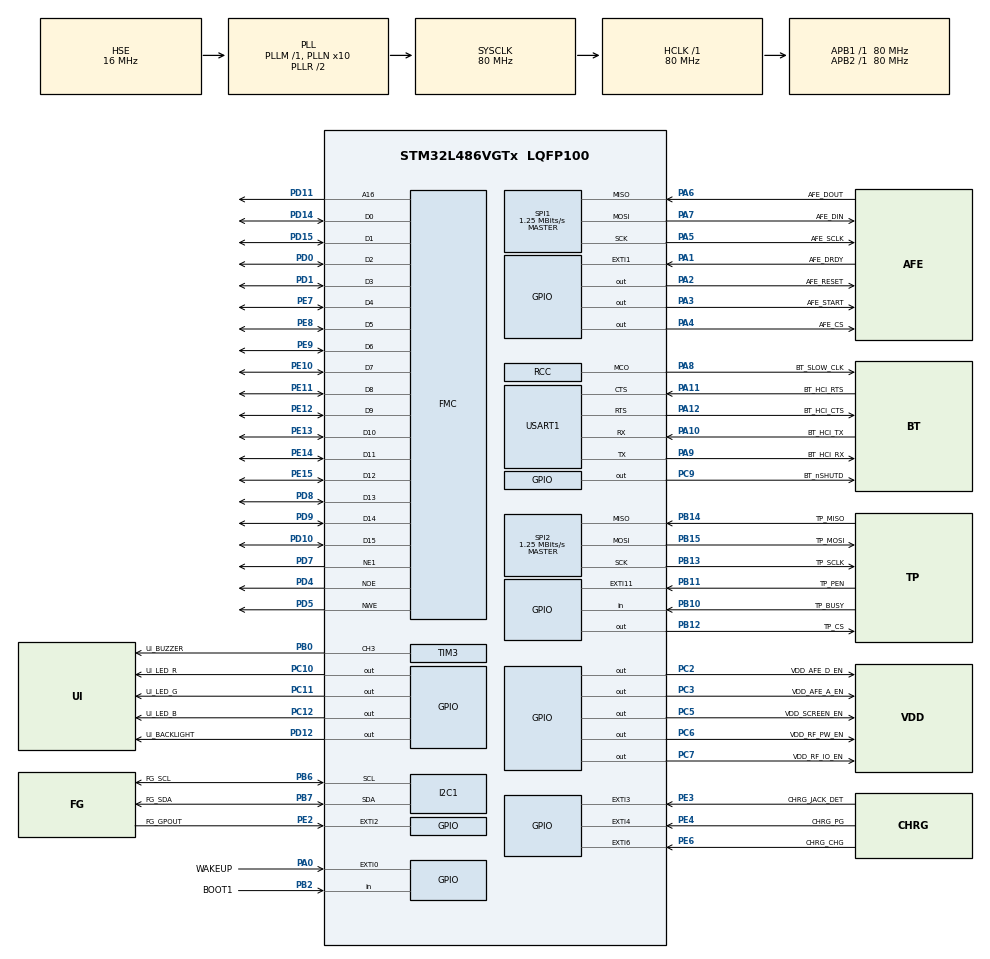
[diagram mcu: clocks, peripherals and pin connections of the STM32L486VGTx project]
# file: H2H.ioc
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Dma.I2C1_RX.1.Direction=DMA_PERIPH_TO_MEMORY
Dma.I2C1_RX.1.Instance=DMA1_Channel7
Dma.I2C1_RX.1.MemDataAlignment=DMA_MDATAALIGN_BYTE
Dma.I2C1_RX.1.MemInc=DMA_MINC_ENABLE
Dma.I2C1_RX.1.Mode=DMA_NORMAL
Dma.I2C1_RX.1.PeriphDataAlignment=DMA_PDATAALIGN_BYTE
Dma.I2C1_RX.1.PeriphInc=DMA_PINC_DISABLE
Dma.I2C1_RX.1.Priority=DMA_PRIORITY_LOW
Dma.I2C1_TX.0.Direction=DMA_MEMORY_TO_PERIPH
Dma.I2C1_TX.0.Instance=DMA1_Channel6
Dma.I2C1_TX.0.MemDataAlignment=DMA_MDATAALIGN_BYTE
Dma.I2C1_TX.0.MemInc=DMA_MINC_ENABLE
Dma.I2C1_TX.0.Mode=DMA_NORMAL
Dma.I2C1_TX.0.PeriphDataAlignment=DMA_PDATAALIGN_BYTE
Dma.I2C1_TX.0.PeriphInc=DMA_PINC_DISABLE
Dma.I2C1_TX.0.Priority=DMA_PRIORITY_LOW
Dma.MEMTOMEM.8.Direction=DMA_MEMORY_TO_MEMORY
Dma.MEMTOMEM.8.Instance=DMA2_Channel1
Dma.MEMTOMEM.8.MemDataAlignment=DMA_MDATAALIGN_BYTE
Dma.MEMTOMEM.8.MemInc=DMA_MINC_DISABLE
Dma.MEMTOMEM.8.Mode=DMA_NORMAL
Dma.MEMTOMEM.8.PeriphDataAlignment=DMA_PDATAALIGN_BYTE
Dma.MEMTOMEM.8.PeriphInc=DMA_PINC_DISABLE
Dma.MEMTOMEM.8.Priority=DMA_PRIORITY_LOW
Dma.Request0=I2C1_TX
Dma.Request1=I2C1_RX
Dma.Request2=SPI1_TX
Dma.Request3=SPI1_RX
Dma.Request4=SPI2_TX
Dma.Request5=SPI2_RX
Dma.Request6=USART1_TX
Dma.Request7=USART1_RX
Dma.Request8=MEMTOMEM
Dma.SPI1_RX.3.Direction=DMA_PERIPH_TO_MEMORY
Dma.SPI1_RX.3.Instance=DMA1_Channel2
Dma.SPI1_RX.3.MemDataAlignment=DMA_MDATAALIGN_BYTE
Dma.SPI1_RX.3.MemInc=DMA_MINC_ENABLE
Dma.SPI1_RX.3.Mode=DMA_NORMAL
Dma.SPI1_RX.3.PeriphDataAlignment=DMA_PDATAALIGN_BYTE
Dma.SPI1_RX.3.PeriphInc=DMA_PINC_DISABLE
Dma.SPI1_RX.3.Priority=DMA_PRIORITY_VERY_HIGH
Dma.SPI1_TX.2.Direction=DMA_MEMORY_TO_PERIPH
Dma.SPI1_TX.2.Instance=DMA1_Channel3
Dma.SPI1_TX.2.MemDataAlignment=DMA_MDATAALIGN_BYTE
Dma.SPI1_TX.2.MemInc=DMA_MINC_ENABLE
Dma.SPI1_TX.2.Mode=DMA_NORMAL
Dma.SPI1_TX.2.PeriphDataAlignment=DMA_PDATAALIGN_BYTE
Dma.SPI1_TX.2.PeriphInc=DMA_PINC_DISABLE
Dma.SPI1_TX.2.Priority=DMA_PRIORITY_VERY_HIGH
Dma.SPI2_RX.5.Direction=DMA_PERIPH_TO_MEMORY
Dma.SPI2_RX.5.Instance=DMA1_Channel4
Dma.SPI2_RX.5.MemDataAlignment=DMA_MDATAALIGN_BYTE
Dma.SPI2_RX.5.MemInc=DMA_MINC_ENABLE
Dma.SPI2_RX.5.Mode=DMA_NORMAL
Dma.SPI2_RX.5.PeriphDataAlignment=DMA_PDATAALIGN_BYTE
Dma.SPI2_RX.5.PeriphInc=DMA_PINC_DISABLE
Dma.SPI2_RX.5.Priority=DMA_PRIORITY_MEDIUM
Dma.SPI2_TX.4.Direction=DMA_MEMORY_TO_PERIPH
Dma.SPI2_TX.4.Instance=DMA1_Channel5
Dma.SPI2_TX.4.MemDataAlignment=DMA_MDATAALIGN_BYTE
Dma.SPI2_TX.4.MemInc=DMA_MINC_ENABLE
Dma.SPI2_TX.4.Mode=DMA_NORMAL
Dma.SPI2_TX.4.PeriphDataAlignment=DMA_PDATAALIGN_BYTE
Dma.SPI2_TX.4.PeriphInc=DMA_PINC_DISABLE
Dma.SPI2_TX.4.Priority=DMA_PRIORITY_MEDIUM
Dma.USART1_RX.7.Direction=DMA_PERIPH_TO_MEMORY
Dma.USART1_RX.7.Instance=DMA2_Channel7
Dma.USART1_RX.7.MemDataAlignment=DMA_MDATAALIGN_BYTE
Dma.USART1_RX.7.MemInc=DMA_MINC_ENABLE
Dma.USART1_RX.7.Mode=DMA_NORMAL
Dma.USART1_RX.7.PeriphDataAlignment=DMA_PDATAALIGN_BYTE
Dma.USART1_RX.7.PeriphInc=DMA_PINC_DISABLE
Dma.USART1_RX.7.Priority=DMA_PRIORITY_HIGH
Dma.USART1_TX.6.Direction=DMA_MEMORY_TO_PERIPH
Dma.USART1_TX.6.Instance=DMA2_Channel6
Dma.USART1_TX.6.MemDataAlignment=DMA_MDATAALIGN_BYTE
Dma.USART1_TX.6.MemInc=DMA_MINC_ENABLE
Dma.USART1_TX.6.Mode=DMA_NORMAL
Dma.USART1_TX.6.PeriphDataAlignment=DMA_PDATAALIGN_BYTE
Dma.USART1_TX.6.PeriphInc=DMA_PINC_DISABLE
Dma.USART1_TX.6.Priority=DMA_PRIORITY_HIGH
FMC.AddressSetupTime1=5
FMC.BusTurnAroundDuration1=5
FMC.DataSetupTime1=5
FREERTOS.Tasks01=defaultTask,0,128,StartDefaultTask,Default
FREERTOS.configCHECK_FOR_STACK_OVERFLOW=2
FREERTOS.configMAX_TASK_NAME_LEN=24
FREERTOS.configMINIMAL_STACK_SIZE=64
FREERTOS.configTOTAL_HEAP_SIZE=64000
FREERTOS.configUSE_COUNTING_SEMAPHORES=1
FREERTOS.configUSE_RECURSIVE_MUTEXES=1
FREERTOS.configUSE_TICKLESS_IDLE=1
I2C1.Analog_Filter=I2C_ANALOGFILTER_DISABLE
I2C1.Speed=50
I2C1.Timing=0x30408EFF
Mcu.Family=STM32L4
Mcu.Name=STM32L486VGTx
Mcu.Package=LQFP100
NVIC.DMA1_Channel2_IRQn=true\:6\:0\:true\:false\:true\:true
NVIC.DMA1_Channel3_IRQn=true\:6\:0\:true\:false\:true\:true
NVIC.DMA1_Channel4_IRQn=true\:8\:0\:true\:false\:true\:true
NVIC.DMA1_Channel5_IRQn=true\:8\:0\:true\:false\:true\:true
NVIC.DMA1_Channel6_IRQn=true\:9\:0\:true\:false\:true\:true
NVIC.DMA1_Channel7_IRQn=true\:9\:0\:true\:false\:true\:true
NVIC.DMA2_Channel6_IRQn=true\:7\:0\:true\:false\:true\:true
NVIC.DMA2_Channel7_IRQn=true\:7\:0\:true\:false\:true\:true
NVIC.EXTI0_IRQn=true\:5\:0\:false\:false\:true\:true
NVIC.EXTI15_10_IRQn=true\:7\:0\:true\:false\:true\:true
NVIC.EXTI1_IRQn=true\:6\:0\:true\:false\:true\:true
NVIC.EXTI2_IRQn=true\:8\:0\:true\:false\:true\:true
NVIC.EXTI3_IRQn=true\:8\:0\:true\:false\:true\:true
NVIC.EXTI4_IRQn=true\:8\:0\:true\:false\:true\:true
NVIC.EXTI9_5_IRQn=true\:5\:0\:true\:false\:true\:true
NVIC.PriorityGroup=NVIC_PRIORITYGROUP_4
NVIC.RTC_Alarm_IRQn=true\:10\:0\:true\:false\:true\:true
NVIC.TIM4_IRQn=true\:10\:0\:true\:false\:true\:true
PA0.GPIO_Label=WAKEUP
PA0.Signal=GPXTI0
PA1.GPIO_Label=AFE_DRDY
PA1.Signal=GPXTI1
PA10.GPIO_Label=BT_HCI_TX
PA10.Mode=Asynchronous
PA10.Signal=USART1_RX
PA11.GPIO_Label=BT_HCI_RTS
PA11.Mode=CTS_RTS
PA11.Signal=USART1_CTS
PA12.GPIO_Label=BT_HCI_CTS
PA12.Mode=CTS_RTS
PA12.Signal=USART1_RTS
PA13.Mode=Serial_Wire
PA13.Signal=SYS_JTMS-SWDIO
PA14.Mode=Serial_Wire
PA14.Signal=SYS_JTCK-SWCLK
PA2.GPIO_Label=AFE_RESET
PA2.PinState=GPIO_PIN_RESET
PA2.Signal=GPIO_Output
PA3.GPIO_Label=AFE_START
PA3.Signal=GPIO_Output
PA4.GPIO_Label=AFE_CS
PA4.PinState=GPIO_PIN_RESET
PA4.Signal=GPIO_Output
PA5.GPIO_Label=AFE_SCLK
PA5.Mode=Full_Duplex_Master
PA5.Signal=SPI1_SCK
PA6.GPIO_Label=AFE_DOUT
PA6.Mode=Full_Duplex_Master
PA6.Signal=SPI1_MISO
PA7.GPIO_Label=AFE_DIN
PA7.Mode=Full_Duplex_Master
PA7.Signal=SPI1_MOSI
PA8.GPIO_Label=BT_SLOW_CLK
PA8.Mode=Clock-out
PA8.Signal=RCC_MCO
PA9.GPIO_Label=BT_HCI_RX
PA9.Mode=Asynchronous
PA9.Signal=USART1_TX
PB0.GPIO_Label=UI_BUZZER
PB0.Signal=S_TIM3_CH3
PB10.GPIO_Label=TP_BUSY
PB10.Signal=GPIO_Input
PB11.GPIO_Label=TP_PEN
PB11.Signal=GPXTI11
PB12.GPIO_Label=TP_CS
PB12.PinState=GPIO_PIN_RESET
PB12.Signal=GPIO_Output
PB13.GPIO_Label=TP_SCLK
PB13.Mode=Full_Duplex_Master
PB13.Signal=SPI2_SCK
PB14.GPIO_Label=TP_MISO
PB14.Mode=Full_Duplex_Master
PB14.Signal=SPI2_MISO
PB15.GPIO_Label=TP_MOSI
PB15.Mode=Full_Duplex_Master
PB15.Signal=SPI2_MOSI
PB2.GPIO_Label=BOOT1
PB2.Signal=GPIO_Input
PB6.GPIO_Label=FG_SCL
PB6.Mode=I2C
PB6.Signal=I2C1_SCL
PB7.GPIO_Label=FG_SDA
PB7.Mode=I2C
PB7.Signal=I2C1_SDA
PC10.GPIO_Label=UI_LED_R
PC10.Signal=GPIO_Output
PC11.GPIO_Label=UI_LED_G
PC11.Signal=GPIO_Output
PC12.GPIO_Label=UI_LED_B
PC12.Signal=GPIO_Output
PC14/OSC32_IN.GPIO_Label=OSC32_IN
PC14/OSC32_IN.Mode=LSE-External-Oscillator
PC14/OSC32_IN.Signal=RCC_OSC32_IN
PC15/OSC32_OUT.GPIO_Label=OSC32_OUT
PC15/OSC32_OUT.Mode=LSE-External-Oscillator
PC15/OSC32_OUT.Signal=RCC_OSC32_OUT
PC2.GPIO_Label=VDD_AFE_D_EN
PC2.Signal=GPIO_Output
PC3.GPIO_Label=VDD_AFE_A_EN
PC3.Signal=GPIO_Output
PC5.GPIO_Label=VDD_SCREEN_EN
PC5.Signal=GPIO_Output
PC6.GPIO_Label=VDD_RF_PW_EN
PC6.Signal=GPIO_Output
PC7.GPIO_Label=VDD_RF_IO_EN
PC7.Signal=GPIO_Output
PC9.GPIO_Label=BT_nSHUTD
PC9.Signal=GPIO_Output
PD0.Mode=16b-d1
PD0.Signal=FMC_D2
PD1.Mode=16b-d1
PD1.Signal=FMC_D3
PD10.Mode=16b-d1
PD10.Signal=FMC_D15
PD11.Mode=A16_1
PD11.Signal=FMC_A16
PD12.GPIO_Label=UI_BACKLIGHT
PD12.Signal=GPIO_Output
PD14.Mode=16b-d1
PD14.Signal=FMC_D0
PD15.Mode=16b-d1
PD15.Signal=FMC_D1
PD4.Mode=Lcd1
PD4.Signal=FMC_NOE
PD5.Mode=Lcd1
PD5.Signal=FMC_NWE
PD7.Mode=NorPsramChipSelect1_1
PD7.Signal=FMC_NE1
PD8.Mode=16b-d1
PD8.Signal=FMC_D13
PD9.Mode=16b-d1
PD9.Signal=FMC_D14
PE10.Mode=16b-d1
PE10.Signal=FMC_D7
PE11.Mode=16b-d1
PE11.Signal=FMC_D8
PE12.Mode=16b-d1
PE12.Signal=FMC_D9
PE13.Mode=16b-d1
PE13.Signal=FMC_D10
PE14.Mode=16b-d1
PE14.Signal=FMC_D11
PE15.Mode=16b-d1
PE15.Signal=FMC_D12
PE2.GPIO_Label=FG_GPOUT
PE2.Signal=GPXTI2
PE3.GPIO_Label=CHRG_JACK_DET
PE3.Signal=GPXTI3
PE4.GPIO_Label=CHRG_PG
PE4.Signal=GPXTI4
PE6.GPIO_Label=CHRG_CHG
PE6.Signal=GPXTI6
PE7.Mode=16b-d1
PE7.Signal=FMC_D4
PE8.Mode=16b-d1
PE8.Signal=FMC_D5
PE9.Mode=16b-d1
PE9.Signal=FMC_D6
PH0/OSC_IN.GPIO_Label=OSC_IN
PH0/OSC_IN.Mode=HSE-External-Oscillator
PH0/OSC_IN.Signal=RCC_OSC_IN
PH1/OSC_OUT.GPIO_Label=OSC_OUT
PH1/OSC_OUT.Mode=HSE-External-Oscillator
PH1/OSC_OUT.Signal=RCC_OSC_OUT
ProjectManager.HeapSize=0x200
ProjectManager.StackSize=0x400
ProjectManager.TargetToolchain=EWARM
RCC.ADCFreq_Value=64000000
RCC.AHBFreq_Value=80000000
RCC.APB1Freq_Value=80000000
RCC.APB1TimFreq_Value=80000000
RCC.APB2Freq_Value=80000000
RCC.APB2TimFreq_Value=80000000
RCC.CortexFreq_Value=80000000
RCC.EnableCSSLSE=true
RCC.EnbaleCSS=true
RCC.HCLKFreq_Value=80000000
RCC.HSE_VALUE=16000000
RCC.HSI_VALUE=16000000
RCC.MSI_VALUE=4000000
RCC.PLLN=10
RCC.PLLSourceVirtual=RCC_PLLSOURCE_HSE
RCC.RCC_MCO1Source=RCC_MCO1SOURCE_LSE
RCC.RTCClockSelection=RCC_RTCCLKSOURCE_LSE
RCC.SYSCLKFreq_VALUE=80000000
RCC.SYSCLKSource=RCC_SYSCLKSOURCE_PLLCLK
RCC.USBFreq_Value=64000000
RCC.VCOOutputFreq_Value=160000000
RTC.AlarmMask-Alarm\ A=RTC_ALARMMASK_ALL
RTC.Format=RTC_FORMAT_BIN
RTC.Year=16
SH.S_TIM3_CH3.0=TIM3_CH3,PWM Generation3 CH3
SPI1.BaudRatePrescaler=SPI_BAUDRATEPRESCALER_64
SPI1.CLKPhase=SPI_PHASE_2EDGE
SPI1.CalculateBaudRate=1.25 MBits/s
SPI1.DataSize=SPI_DATASIZE_8BIT
SPI1.Mode=SPI_MODE_MASTER
SPI2.BaudRatePrescaler=SPI_BAUDRATEPRESCALER_64
SPI2.CalculateBaudRate=1.25 MBits/s
SPI2.DataSize=SPI_DATASIZE_8BIT
SPI2.Mode=SPI_MODE_MASTER
SPI2.NSSPMode=SPI_NSS_PULSE_DISABLE
TIM3.Channel-PWM\ Generation3\ CH3=TIM_CHANNEL_3
TIM3.ClockDivision=TIM_CLOCKDIVISION_DIV2
TIM3.OCFastMode_PWM-PWM\ Generation3\ CH3=TIM_OCFAST_ENABLE
TIM3.Period=4545
TIM3.Prescaler=75
TIM3.Pulse-PWM\ Generation3\ CH3=2273
TIM4.ClockDivision=TIM_CLOCKDIVISION_DIV2
TIM4.Period=1000
TIM4.Prescaler=40000
USART1.WordLength=UART_WORDLENGTH_8B
VP_FREERTOS_VS_ENABLE.Mode=Enabled
VP_RTC_VS_RTC_Alarm_A_Intern.Mode=Alarm A
VP_TIM3_VS_ClockSourceINT.Mode=Internal
VP_TIM4_VS_ClockSourceINT.Mode=Internal
board=H2H

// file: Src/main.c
/**
  ******************************************************************************
  * File Name          : main.c
  * Description        : Main program body
  ******************************************************************************
  *
  * COPYRIGHT(c) 2016 STMicroelectronics
  *
  * Redistribution and use in source and binary forms, with or without modification,
  * are permitted provided that the following conditions are met:
  *   1. Redistributions of source code must retain the above copyright notice,
  *      this list of conditions and the following disclaimer.
  *   2. Redistributions in binary form must reproduce the above copyright notice,
  *      this list of conditions and the following disclaimer in the documentation
  *      and/or other materials provided with the distribution.
  *   3. Neither the name of STMicroelectronics nor the names of its contributors
  *      may be used to endorse or promote products derived from this software
  *      without specific prior written permission.
  *
  * THIS SOFTWARE IS PROVIDED BY THE COPYRIGHT HOLDERS AND CONTRIBUTORS "AS IS"
  * AND ANY EXPRESS OR IMPLIED WARRANTIES, INCLUDING, BUT NOT LIMITED TO, THE
  * IMPLIED WARRANTIES OF MERCHANTABILITY AND FITNESS FOR A PARTICULAR PURPOSE ARE
  * DISCLAIMED. IN NO EVENT SHALL THE COPYRIGHT HOLDER OR CONTRIBUTORS BE LIABLE
  * FOR ANY DIRECT, INDIRECT, INCIDENTAL, SPECIAL, EXEMPLARY, OR CONSEQUENTIAL
  * DAMAGES (INCLUDING, BUT NOT LIMITED TO, PROCUREMENT OF SUBSTITUTE GOODS OR
  * SERVICES; LOSS OF USE, DATA, OR PROFITS; OR BUSINESS INTERRUPTION) HOWEVER
  * CAUSED AND ON ANY THEORY OF LIABILITY, WHETHER IN CONTRACT, STRICT LIABILITY,
  * OR TORT (INCLUDING NEGLIGENCE OR OTHERWISE) ARISING IN ANY WAY OUT OF THE USE
  * OF THIS SOFTWARE, EVEN IF ADVISED OF THE POSSIBILITY OF SUCH DAMAGE.
  *
  ******************************************************************************
  */
#include "stm32l4xx_hal.h"
#include "cmsis_os.h"
#include "dma.h"
#include "i2c.h"
#include "rtc.h"
#include "spi.h"
#include "tim.h"
#include "usart.h"
#include "gpio.h"
#include "fmc.h"

/* USER CODE BEGIN PV */
/* Private variables ---------------------------------------------------------*/

/* USER CODE END PV */

void SystemClock_Config(void);
void Error_Handler(void);
void MX_FREERTOS_Init(void);
void wakeup_check(void);

/* USER CODE BEGIN PFP */
/* Private function prototypes -----------------------------------------------*/

/* USER CODE END PFP */

int main(void)
{

  /* MCU Configuration----------------------------------------------------------*/

  /* Reset of all peripherals, Initializes the Flash interface and the Systick. */
  HAL_Init();

  /* Configure the system clock */
  SystemClock_Config();

  /* Enable wakeup debug and check */
  HAL_DBGMCU_EnableDBGStandbyMode();
  wakeup_check();

  /* Initialize all configured peripherals */
  MX_GPIO_Init();
  MX_DMA_Init();
  MX_FMC_Init();
  MX_I2C1_Init();
  MX_SPI1_Init();
  MX_SPI2_Init();
  MX_TIM3_Init();
  MX_USART1_UART_Init();
  MX_RTC_Init();
  MX_TIM4_Init();

  /* Call init function for freertos objects (in freertos.c) */
  MX_FREERTOS_Init();

  /* Start scheduler */
  osKernelStart();

  /* We should never get here as control is now taken by the scheduler */

  /* Infinite loop */
  while (1)
  {

  }

}

void wakeup_check(void)
{
  /* Checks if the system is resumed from standby */
  if (__HAL_PWR_GET_FLAG(PWR_FLAG_WU))
  {
    GPIO_InitTypeDef GPIO_InitStruct;

    /* Make falling edge sensitive */
    GPIO_InitStruct.Pin = WAKEUP_Pin;
    GPIO_InitStruct.Mode = GPIO_MODE_IT_FALLING;
    GPIO_InitStruct.Pull = GPIO_NOPULL;
    HAL_GPIO_Init(GPIOA, &GPIO_InitStruct);

    /* Wait */
    HAL_Delay(1000);

    /* If a falling edge has occured
     * the press was not long enough
     * to wake up the device
     */
    if (__HAL_GPIO_EXTI_GET_IT(GPIO_PIN_0) == SET)
    {
      /* Clear interrupt flag */
      __HAL_GPIO_EXTI_CLEAR_IT(GPIO_PIN_0);

      /* Enable wakeup pin and go to sleep */
      HAL_PWR_EnableWakeUpPin(PWR_WAKEUP_PIN1);
      __HAL_PWR_CLEAR_FLAG(PWR_FLAG_WU);
      HAL_PWR_EnterSTANDBYMode();
    }
  }
}

/** System Clock Configuration
*/
void SystemClock_Config(void)
{

  RCC_OscInitTypeDef RCC_OscInitStruct;
  RCC_ClkInitTypeDef RCC_ClkInitStruct;
  RCC_PeriphCLKInitTypeDef PeriphClkInit;

  RCC_OscInitStruct.OscillatorType = RCC_OSCILLATORTYPE_HSE|RCC_OSCILLATORTYPE_LSE;
  RCC_OscInitStruct.HSEState = RCC_HSE_ON;
  RCC_OscInitStruct.LSEState = RCC_LSE_ON;
  RCC_OscInitStruct.PLL.PLLState = RCC_PLL_ON;
  RCC_OscInitStruct.PLL.PLLSource = RCC_PLLSOURCE_HSE;
  RCC_OscInitStruct.PLL.PLLM = 1;
  RCC_OscInitStruct.PLL.PLLN = 10;
  RCC_OscInitStruct.PLL.PLLP = RCC_PLLP_DIV7;
  RCC_OscInitStruct.PLL.PLLQ = RCC_PLLQ_DIV2;
  RCC_OscInitStruct.PLL.PLLR = RCC_PLLR_DIV2;
  if (HAL_RCC_OscConfig(&RCC_OscInitStruct) != HAL_OK)
  {
    Error_Handler();
  }

  RCC_ClkInitStruct.ClockType = RCC_CLOCKTYPE_HCLK|RCC_CLOCKTYPE_SYSCLK
                              |RCC_CLOCKTYPE_PCLK1|RCC_CLOCKTYPE_PCLK2;
  RCC_ClkInitStruct.SYSCLKSource = RCC_SYSCLKSOURCE_PLLCLK;
  RCC_ClkInitStruct.AHBCLKDivider = RCC_SYSCLK_DIV1;
  RCC_ClkInitStruct.APB1CLKDivider = RCC_HCLK_DIV1;
  RCC_ClkInitStruct.APB2CLKDivider = RCC_HCLK_DIV1;
  if (HAL_RCC_ClockConfig(&RCC_ClkInitStruct, FLASH_LATENCY_4) != HAL_OK)
  {
    Error_Handler();
  }

  PeriphClkInit.PeriphClockSelection = RCC_PERIPHCLK_RTC|RCC_PERIPHCLK_USART1
                              |RCC_PERIPHCLK_I2C1;
  PeriphClkInit.Usart1ClockSelection = RCC_USART1CLKSOURCE_PCLK2;
  PeriphClkInit.I2c1ClockSelection = RCC_I2C1CLKSOURCE_PCLK1;
  PeriphClkInit.RTCClockSelection = RCC_RTCCLKSOURCE_LSE;
  if (HAL_RCCEx_PeriphCLKConfig(&PeriphClkInit) != HAL_OK)
  {
    Error_Handler();
  }

  HAL_RCC_MCOConfig(RCC_MCO1, RCC_MCO1SOURCE_LSE, RCC_MCODIV_1);

  HAL_RCC_EnableCSS();

  HAL_RCCEx_EnableLSECSS();

  __HAL_RCC_PWR_CLK_ENABLE();

  if (HAL_PWREx_ControlVoltageScaling(PWR_REGULATOR_VOLTAGE_SCALE1) != HAL_OK)
  {
    Error_Handler();
  }

  HAL_SYSTICK_Config(HAL_RCC_GetHCLKFreq()/1000);

  HAL_SYSTICK_CLKSourceConfig(SYSTICK_CLKSOURCE_HCLK);

  /* SysTick_IRQn interrupt configuration */
  HAL_NVIC_SetPriority(SysTick_IRQn, 15, 0);
}

void Error_Handler(void)
{
  while(1)
  {
  }
}

/************************ (C) COPYRIGHT STMicroelectronics *****END OF FILE****/

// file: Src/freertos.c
/**
  ******************************************************************************
  * File Name          : freertos.c
  * Description        : Code for freertos applications
  ******************************************************************************
  *
  * COPYRIGHT(c) 2016 STMicroelectronics
  *
  * Redistribution and use in source and binary forms, with or without modification,
  * are permitted provided that the following conditions are met:
  *   1. Redistributions of source code must retain the above copyright notice,
  *      this list of conditions and the following disclaimer.
  *   2. Redistributions in binary form must reproduce the above copyright notice,
  *      this list of conditions and the following disclaimer in the documentation
  *      and/or other materials provided with the distribution.
  *   3. Neither the name of STMicroelectronics nor the names of its contributors
  *      may be used to endorse or promote products derived from this software
  *      without specific prior written permission.
  *
  * THIS SOFTWARE IS PROVIDED BY THE COPYRIGHT HOLDERS AND CONTRIBUTORS "AS IS"
  * AND ANY EXPRESS OR IMPLIED WARRANTIES, INCLUDING, BUT NOT LIMITED TO, THE
  * IMPLIED WARRANTIES OF MERCHANTABILITY AND FITNESS FOR A PARTICULAR PURPOSE ARE
  * DISCLAIMED. IN NO EVENT SHALL THE COPYRIGHT HOLDER OR CONTRIBUTORS BE LIABLE
  * FOR ANY DIRECT, INDIRECT, INCIDENTAL, SPECIAL, EXEMPLARY, OR CONSEQUENTIAL
  * DAMAGES (INCLUDING, BUT NOT LIMITED TO, PROCUREMENT OF SUBSTITUTE GOODS OR
  * SERVICES; LOSS OF USE, DATA, OR PROFITS; OR BUSINESS INTERRUPTION) HOWEVER
  * CAUSED AND ON ANY THEORY OF LIABILITY, WHETHER IN CONTRACT, STRICT LIABILITY,
  * OR TORT (INCLUDING NEGLIGENCE OR OTHERWISE) ARISING IN ANY WAY OUT OF THE USE
  * OF THIS SOFTWARE, EVEN IF ADVISED OF THE POSSIBILITY OF SUCH DAMAGE.
  *
  ******************************************************************************
  */

#include "FreeRTOS.h"
#include "task.h"
#include "cmsis_os.h"

/* USER CODE BEGIN Includes */
#include "tasks_ecg.h"

#include "afe.h"
/* USER CODE END Includes */

osThreadId defaultTaskHandle;

/* USER CODE BEGIN Variables */
/* Hardware */
afe_t afe;

/* USER CODE END Variables */

void StartDefaultTask(void const * argument);

void MX_FREERTOS_Init(void); /* (MISRA C 2004 rule 8.1) */

/* USER CODE BEGIN FunctionPrototypes */
void system_init(void);
/* USER CODE END FunctionPrototypes */

/* Pre/Post sleep processing prototypes */
void PreSleepProcessing(uint32_t *ulExpectedIdleTime);
void PostSleepProcessing(uint32_t *ulExpectedIdleTime);

/* Hook prototypes */
void vApplicationStackOverflowHook(xTaskHandle xTask, signed char *pcTaskName);

/* USER CODE BEGIN 4 */
void vApplicationStackOverflowHook(xTaskHandle xTask, signed char *pcTaskName)
{
   /* Run time stack overflow checking is performed if
   configCHECK_FOR_STACK_OVERFLOW is defined to 1 or 2. This hook function is
   called if a stack overflow is detected. */
}
/* USER CODE END 4 */

/* USER CODE BEGIN PREPOSTSLEEP */
void PreSleepProcessing(uint32_t *ulExpectedIdleTime)
{
/* place for user code */
}

void PostSleepProcessing(uint32_t *ulExpectedIdleTime)
{
/* place for user code */
}
/* USER CODE END PREPOSTSLEEP */

/* Init FreeRTOS */

void MX_FREERTOS_Init(void) {
  /* USER CODE BEGIN Init */
  /* Initialize system */
  system_init();

  /* Init tasks */
  tasks_ecg_init();

  /* Start tasks */
  tasks_ecg_start();

  /* USER CODE END Init */

  /* Create the thread(s) */
  /* definition and creation of defaultTask */
  osThreadDef(defaultTask, StartDefaultTask, osPriorityNormal, 0, 128);
  defaultTaskHandle = osThreadCreate(osThread(defaultTask), NULL);

}

/* StartDefaultTask function */
void StartDefaultTask(void const * argument)
{

  for(;;)
  {
    osDelay(1);
  }
}

/* USER CODE BEGIN Application */
void system_init(void)
{
  afe_init(&afe, &hspi1);
  afe_test_signal_on(&afe);
}

/* USER CODE END Application */

/************************ (C) COPYRIGHT STMicroelectronics *****END OF FILE****/
